# WBZ450 register map
Vendor: Microchip
Registers are 32-bit, read-write, reset 0x0 unless marked. A register's access mark holds for its fields unless they carry their own. Addresses are absolute, and some are shared; only a register's first bit layout is shown; [hi:lo] are bit positions; {n}, {i} and the like mark numbered series; 'fields as' and 'values as' point back to an identical list.

## RAMECC
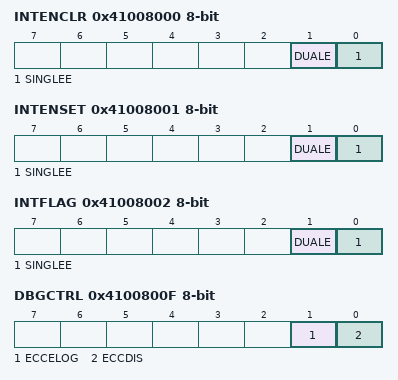
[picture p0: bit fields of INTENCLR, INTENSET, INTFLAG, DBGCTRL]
0x41008000 INTENCLR 8-bit
  [1] DUALE — Dual Bit ECC Error Interrupt Enable Clear
  [0] SINGLEE — Single Bit ECC Error Interrupt Enable Clear
0x41008001 INTENSET 8-bit
  [1] DUALE — Dual Bit ECC Error Interrupt Enable Set
  [0] SINGLEE — Single Bit ECC Error Interrupt Enable Set
0x41008002 INTFLAG 8-bit
  [1] DUALE — Dual Bit ECC Error Interrupt
  [0] SINGLEE — Single Bit ECC Error Interrupt
0x41008003 STATUS 8-bit ro
  [0] ECCDIS — ECC Disable
0x41008004 ERRADDR ro
  [17:0] ERRADDR — Error Address
0x4100800F DBGCTRL 8-bit
  [1] ECCELOG — ECC Error Log
  [0] ECCDIS — ECC Disable

## ARB
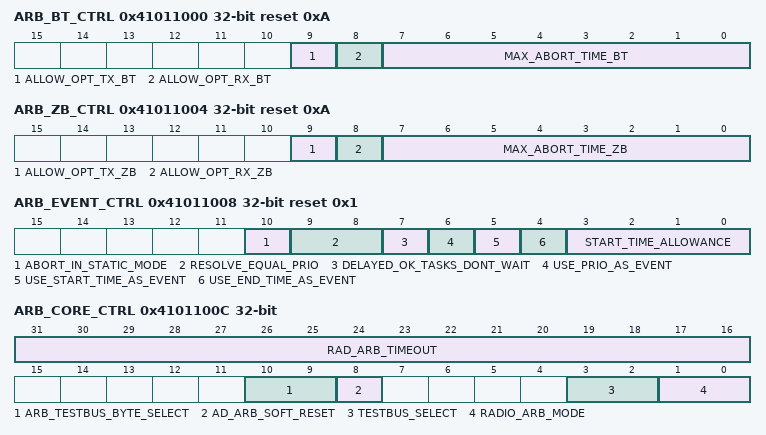
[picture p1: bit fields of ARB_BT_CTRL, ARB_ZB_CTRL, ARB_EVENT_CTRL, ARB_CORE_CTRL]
0x41011000 ARB_BT_CTRL reset 0xA
  [9] ALLOW_OPT_TX_BT — BT allow optimistic tx
  [8] ALLOW_OPT_RX_BT — BT allow optimistic rx
  [7:0] MAX_ABORT_TIME_BT — BT max abort time
0x41011004 ARB_ZB_CTRL reset 0xA
  [9] ALLOW_OPT_TX_ZB — ZB allow optimistic tx
  [8] ALLOW_OPT_RX_ZB — ZB allow optimistic rx
  [7:0] MAX_ABORT_TIME_ZB — ZB max abort time
0x41011008 ARB_EVENT_CTRL reset 0x1
  [10] ABORT_IN_STATIC_MODE
  [9:8] RESOLVE_EQUAL_PRIO
  [7] DELAYED_OK_TASKS_DONT_WAIT
  [6] USE_PRIO_AS_EVENT
  [5] USE_START_TIME_AS_EVENT
  [4] USE_END_TIME_AS_EVENT
  [3:0] START_TIME_ALLOWANCE — minimum change needed in the start time to be considered as an arbitration event.
0x4101100C ARB_CORE_CTRL
  [31:16] RAD_ARB_TIMEOUT, [10:9] ARB_TESTBUS_BYTE_SELECT, [8] AD_ARB_SOFT_RESET, [3:2] TESTBUS_SELECT, [1:0] RADIO_ARB_MODE
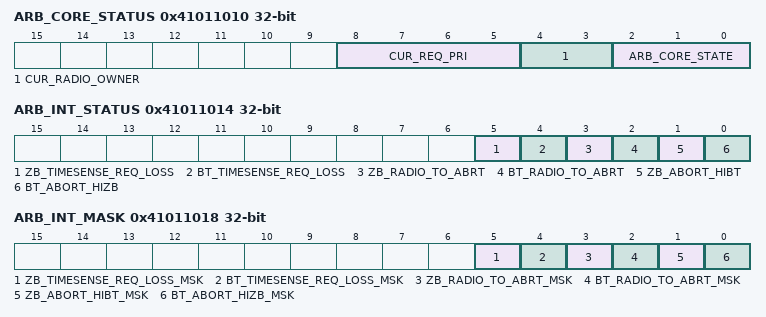
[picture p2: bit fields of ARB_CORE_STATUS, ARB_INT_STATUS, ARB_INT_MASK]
0x41011010 ARB_CORE_STATUS ro
  [8:5] CUR_REQ_PRI, [4:3] CUR_RADIO_OWNER, [2:0] ARB_CORE_STATE
0x41011014 ARB_INT_STATUS
  [5] ZB_TIMESENSE_REQ_LOSS, [4] BT_TIMESENSE_REQ_LOSS, [3] ZB_RADIO_TO_ABRT, [2] BT_RADIO_TO_ABRT, [1] ZB_ABORT_HIBT, [0] BT_ABORT_HIZB
0x41011018 ARB_INT_MASK
  [5] ZB_TIMESENSE_REQ_LOSS_MSK, [4] BT_TIMESENSE_REQ_LOSS_MSK, [3] ZB_RADIO_TO_ABRT_MSK, [2] BT_RADIO_TO_ABRT_MSK, [1] ZB_ABORT_HIBT_MSK, [0] BT_ABORT_HIZB_MSK

## BLE
0x410124B8 DPLL_RG1 16-bit reset not defined
  [15:0] DPLL_RG1BITS
0x410124BA DPLL_RG2 16-bit reset not defined
  [15:0] DPLL_RG2BITS

## BTZBSYS
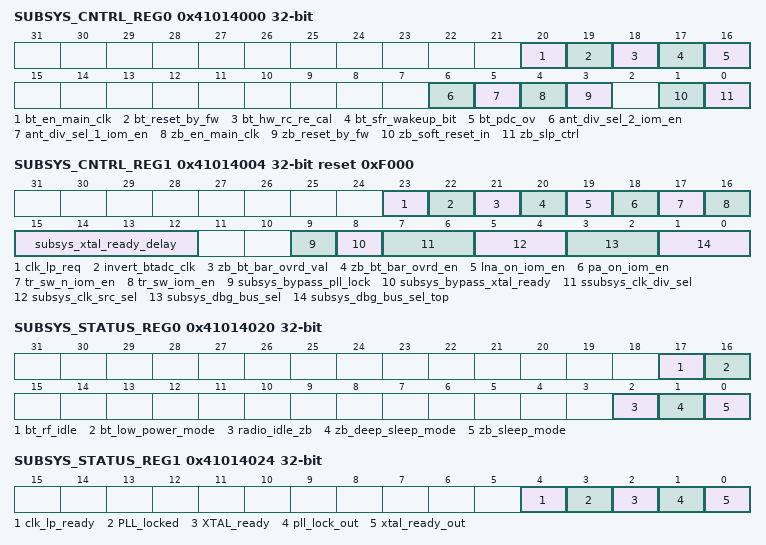
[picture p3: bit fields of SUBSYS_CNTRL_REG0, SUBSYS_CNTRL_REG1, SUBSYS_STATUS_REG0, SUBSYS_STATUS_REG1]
0x41014000 SUBSYS_CNTRL_REG0
  [20] bt_en_main_clk, [19] bt_reset_by_fw, [18] bt_hw_rc_re_cal, [17] bt_sfr_wakeup_bit, [16] bt_pdc_ov, [6] ant_div_sel_2_iom_en, [5] ant_div_sel_1_iom_en, [4] zb_en_main_clk, [3] zb_reset_by_fw, [1] zb_soft_reset_in, [0] zb_slp_ctrl
0x41014004 SUBSYS_CNTRL_REG1 reset 0xF000
  [23] clk_lp_req
  [22] invert_btadc_clk
  [21] zb_bt_bar_ovrd_val
  [20] zb_bt_bar_ovrd_en
  [19] lna_on_iom_en
  [18] pa_on_iom_en
  [17] tr_sw_n_iom_en
  [16] tr_sw_iom_en
  [15:12] subsys_xtal_ready_delay
  [9] subsys_bypass_pll_lock
  [8] subsys_bypass_xtal_ready
  [7:6] ssubsys_clk_div_sel — subsys_clk_div_sel
  [5:4] subsys_clk_src_sel
  [3:2] subsys_dbg_bus_sel
  [1:0] subsys_dbg_bus_sel_top
0x41014020 SUBSYS_STATUS_REG0
  [17] bt_rf_idle, [16] bt_low_power_mode, [2] radio_idle_zb, [1] zb_deep_sleep_mode, [0] zb_sleep_mode
0x41014024 SUBSYS_STATUS_REG1
  [4] clk_lp_ready, [3] PLL_locked, [2] XTAL_ready, [1] pll_lock_out, [0] xtal_ready_out

## AES
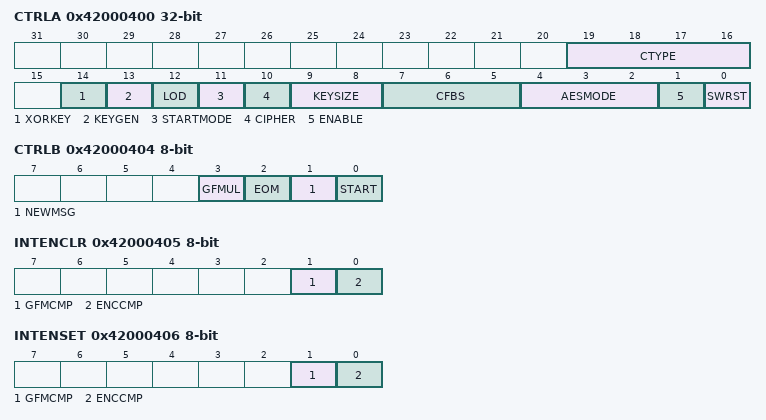
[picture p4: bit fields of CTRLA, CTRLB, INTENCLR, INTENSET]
0x42000400 CTRLA
  [19:16] CTYPE — Counter Measure Type
  [14] XORKEY — XOR Key Operation
    0=NONE (No effect); 1=XOR (The user keyword gets XORed with the previous keyword register content.)
  [13] KEYGEN — Last Key Generation
    0=NONE (No effect); 1=LAST (Start Computation of the last NK words of the expanded key)
  [12] LOD — Last Output Data Mode
    0=NONE (No effect); 1=LAST (Start encryption in Last Output Data mode)
  [11] STARTMODE — Start Mode Select
    0=MANUAL (Start Encryption / Decryption in Manual mode); 1=AUTO (Start Encryption / Decryption in Auto mode)
  [10] CIPHER — Cipher Mode
    0=DEC (Decryption); 1=ENC (Encryption)
  [9:8] KEYSIZE — Encryption Key Size
    0=128BIT (128-bit Key for Encryption / Decryption); 1=192BIT (192-bit Key for Encryption / Decryption); 2=256BIT (256-bit Key for Encryption / Decryption)
  [7:5] CFBS — Cipher Feedback Block Size
    0=128BIT (128-bit Input data block for Encryption/Decryption in Cipher Feedback mode); 1=64BIT (64-bit Input data block for Encryption/Decryption in Cipher Feedback mode); 2=32BIT (32-bit Input data block for Encryption/Decryption in Cipher Feedback mode); 3=16BIT (16-bit Input data block for Encryption/Decryption in Cipher Feedback mode); 4=8BIT (8-bit Input data block for Encryption/Decryption in Cipher Feedback mode)
  [4:2] AESMODE — AES Modes of operation
    0=ECB (Electronic code book mode); 1=CBC (Cipher block chaining mode); 2=OFB (Output feedback mode); 3=CFB (Cipher feedback mode); 4=COUNTER (Counter mode); 5=CCM (CCM mode); 6=GCM (Galois counter mode)
  [1] ENABLE
  [0] SWRST — Software Reset
0x42000404 CTRLB 8-bit
  [3] GFMUL — GF Multiplication
  [2] EOM — End of message
  [1] NEWMSG — New message
  [0] START — Start Encryption/Decryption
0x42000405 INTENCLR 8-bit
  [1] GFMCMP — GF Multiplication Complete Interrupt Enable
  [0] ENCCMP — Encryption Complete Interrupt Enable
0x42000406 INTENSET 8-bit
  fields as INTENCLR
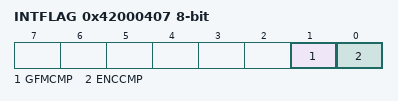
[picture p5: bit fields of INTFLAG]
0x42000407 INTFLAG 8-bit
  [1] GFMCMP — GF Multiplication Complete
  [0] ENCCMP — Encryption Complete
0x42000408 DATABUFPTR 8-bit
  [1:0] INDATAPTR — Input Data Pointer
0x42000409 DBGCTRL 8-bit
  [0] DBGRUN — Debug Run
{0x4200040C+4i} KEYWORD{i} wo (i=0..7)
0x42000438 INDATA
{0x4200043C+4i} INTVECTV{i} wo (i=0..3)
{0x4200045C+4i} HASHKEY{i} (i=0..3)
{0x4200046C+4i} GHASH{i} (i=0..3)
0x42000480 CIPLEN
0x42000484 RANDSEED
